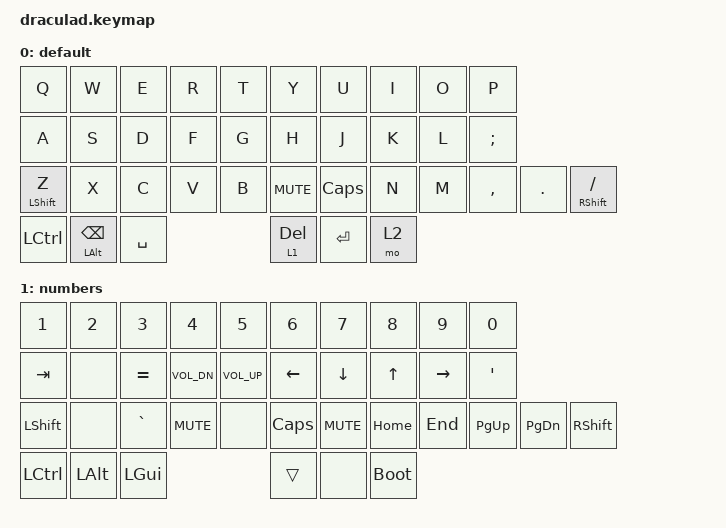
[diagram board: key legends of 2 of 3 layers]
/*
 * Copyright (c) 2020 The ZMK Contributors
 *
 * SPDX-License-Identifier: MIT
 */

#include <behaviors.dtsi>
#include <dt-bindings/zmk/keys.h>
#include <dt-bindings/zmk/bt.h>
#include <dt-bindings/zmk/outputs.h>
#include <dt-bindings/zmk/rgb.h>

/ {
    keymap {
        compatible = "zmk,keymap";

        default {

//  TODO: MOD-MORPHS for coding (as many symbols as possible on first layer)
// --------------------------------------------------------------------------------------------------------------------------------------------------------------------
//  Q    |  W  |  E  |  R  |  T  |           |  Y  |  U  |  I  |    O    |  P   |
//  A    |  S  |  D  |  F  |  G  |           |  H  |  J  |  K  |    L    |  ;   |
// Lsft/Z|  X  |  C  |  V  |  B  |           |  N  |  M  |  ,  |    .    |Rsft//|
//      | LCTL | Bspc/LALT | SPC | CAPS| MUTE| Del/Num | Ent | Sym |
           bindings = <
            &kp Q &kp W &kp E &kp R &kp T &kp Y &kp U &kp I &kp O &kp P
            &kp A &kp S &kp D &kp F &kp G &kp H &kp J &kp K &kp L &kp SEMI
            &mt LSHFT Z &kp X &kp C &kp V &kp B &kp C_MUTE &kp CAPS &kp N &kp M &kp COMMA &kp DOT &mt RSHFT FSLH
            &kp LCTRL &mt LALT BSPC &kp SPACE &lt 1 DEL &kp RET &mo 2
            >;
            sensor-bindings = <&inc_dec_kp LG(Z) LG(X) &inc_dec_kp PG_UP PG_DN>;
        };
        numbers {
// --------------------------------------------------------------------------------------------------------------------------------------------------------------------
//  1  |    2   |  3     |  4  |  5  |           |  6  |  7  |  8  |  9  |  0  |
// TAB |        | =      | VOL-| VOL+|           |  <  |  v  |  ∧  |  >  |  '  |
// Lsft|        | `      | MUTE|     |           | HOME| END | PGUP| PGDN| Rsft|
//               | LCTL | LALT| LMOD | CAPS| MUTE| Num |     | BL-reset |
           bindings = <
            &kp N1 &kp N2 &kp N3 &kp N4 &kp N5 &kp N6 &kp N7 &kp N8 &kp N9 &kp N0
            &kp TAB &none &kp EQUAL &kp C_VOL_DN &kp C_VOL_UP &kp LEFT &kp DOWN &kp UP &kp RIGHT &kp SQT
            &kp LSHFT &none &kp GRAVE &kp C_MUTE &none &kp CAPS &kp C_MUTE &kp HOME &kp END &kp PG_UP &kp PG_DN &kp RSHFT
            &kp LCTRL &kp LALT &kp LGUI &trans &none &bootloader
            >;
        };
        symbols {
// --------------------------------------------------------------------------------------------------------------------------------------------------------------------
// ESC |  F1 |  F2 |  F3 |  F4 |                | OUT_USB | OUT_BLE | BT_PRV  |  BT_NXT  |  -   |
// CAPS|  F5 |  F6 |  F7 |  F8 |                |    [    |    ]    | BT_SEL0 |  BT_CLR  |  \   |
// LSFT|  F9 | F10 | F11 | F12 |                | RGB_TOG | RGB_EFF |         |          | RSFT |
//         | LCTL | LALD| LMOD | CAPS  | MUTE   |  RESET  |         |   SYM   |
           bindings = <
            &kp ESC &kp F1 &kp F2 &kp F3 &kp F4 &out OUT_USB &out OUT_BLE &bt BT_PRV &bt BT_NXT &kp MINUS
            &kp CAPS &kp F5 &kp F6 &kp F7 &kp F8 &kp LBKT &kp RBKT &bt BT_SEL 0 &bt BT_CLR &kp BSLH
            &kp LSHFT &kp F9 &kp F10 &kp F11 &kp F12 &kp CAPS &kp C_MUTE &rgb_ug RGB_TOG &rgb_ug RGB_EFF &none &kp RSHFT
            &kp LCTRL &kp LALT &kp LGUI &reset &none &trans
           >;

        };
    };
};
